VERSION ""

NS_ :

BS_: 500000

BU_: TITA_SENDER VCU BCM ADAS ICC GW

VAL_ 0x399 TrafficLightState 0 "Unknown" 1 "Red" 2 "Yellow_Flashing" 3 "Yellow" 4 "Red_Flashing" 5 "Unknown_5" 6 "Unknown_6" 7 "Green" ;
VAL_ 0x399 LightValid 0 "Invalid" 1 "Valid" ;
VAL_ 0x449 IntersectionReachable 0 "Not_Reachable" 1 "Reachable" ;
VAL_ 0x399 SignalPhaseID 0 "Phase_A" 1 "Phase_B" 2 "Phase_C" 3 "Phase_D" 4 "Phase_E" 5 "Phase_F" 6 "Phase_G" 7 "Phase_H" 8 "Phase_I" 9 "Phase_J" 10 "Phase_K" 11 "Phase_L" 12 "Phase_M" 13 "Phase_N" 14 "Phase_O" 15 "Phase_P" ;

CM_ VCU "Vehicle Control Unit - 整车控制器";
CM_ BCM "Body Control Module - 车身控制器";
CM_ ADAS "Advanced Driver Assistance System - 高级驾驶辅助系统";
CM_ ICC "Intelligent Cockpit Controller - 智能座舱/V2X";
CM_ TITA_SENDER "TITA CAN-BLE Transmitter - 无线发射器";
CM_ GW "Gateway - 网关";

BO_ 273 VehicleControlStatus: 8 ADAS
 SG_ VC_Active : 0|16@1+ (1,0) [0|65535] "" TITA_SENDER
 SG_ VC_Status : 16|16@1+ (1,0) [0|65535] "" TITA_SENDER

BO_ 325 GearDriveMode: 8 VCU
 SG_ Gear_Position : 29|2@1+ (1,0) [0|3] "" TITA_SENDER
 SG_ Drive_Mode : 12|4@1+ (1,0) [0|15] "" TITA_SENDER

BO_ 605 SteerAngle: 6 VCU
 SG_ SteerAngle_Status : 24|3@1+ (1,0) [0|7] "" TITA_SENDER
 SG_ SteerAngle_Value : 16|8@1+ (0.5,-64) [-64|63.5] "deg" TITA_SENDER

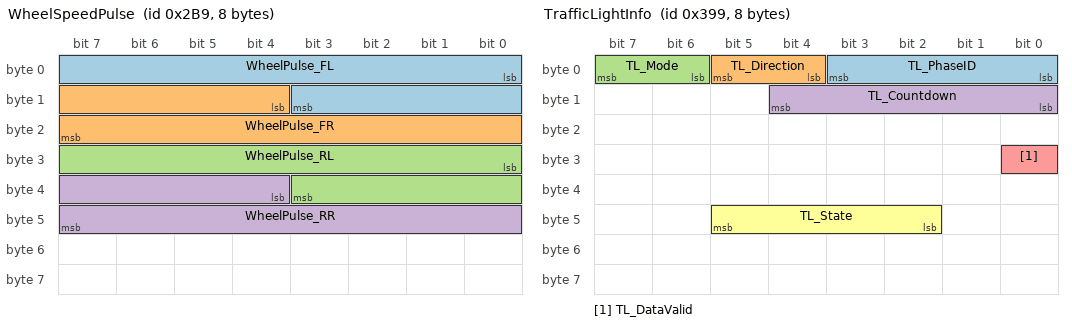
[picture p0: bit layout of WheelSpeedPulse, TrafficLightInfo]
BO_ 697 WheelSpeedPulse: 8 VCU
 SG_ WheelPulse_FL : 0|12@1+ (1,0) [0|4095] "" TITA_SENDER
 SG_ WheelPulse_FR : 12|12@1+ (1,0) [0|4095] "" TITA_SENDER
 SG_ WheelPulse_RL : 24|12@1+ (1,0) [0|4095] "" TITA_SENDER
 SG_ WheelPulse_RR : 36|12@1+ (1,0) [0|4095] "" TITA_SENDER

BO_ 905 VehicleSpeed: 8 VCU
 SG_ Vehicle_Speed : 0|10@1+ (0.1,0) [0|102.3] "km/h" TITA_SENDER

BO_ 921 TrafficLightInfo: 8 ICC
 SG_ TL_PhaseID : 0|4@1+ (1,0) [0|15] "" TITA_SENDER
 SG_ TL_Direction : 4|2@1+ (1,0) [0|3] "" TITA_SENDER
 SG_ TL_Mode : 6|2@1+ (1,0) [0|3] "" TITA_SENDER
 SG_ TL_Countdown : 8|5@1+ (1,0) [0|31] "s" TITA_SENDER
 SG_ TL_DataValid : 24|1@1+ (1,0) [0|1] "" TITA_SENDER
 SG_ TL_State : 42|4@1+ (1,0) [0|15] "" TITA_SENDER

BO_ 925 StopLineDistance: 5 ICC
 SG_ SLD_Status : 16|2@1+ (1,0) [0|3] "" TITA_SENDER
 SG_ SLD_Distance : 21|12@1+ (0.1,0) [0|409.5] "m" TITA_SENDER

BO_ 1097 IntersectionInfo: 3 ICC
 SG_ Intersection_Reachable : 3|1@1+ (1,0) [0|1] "" TITA_SENDER

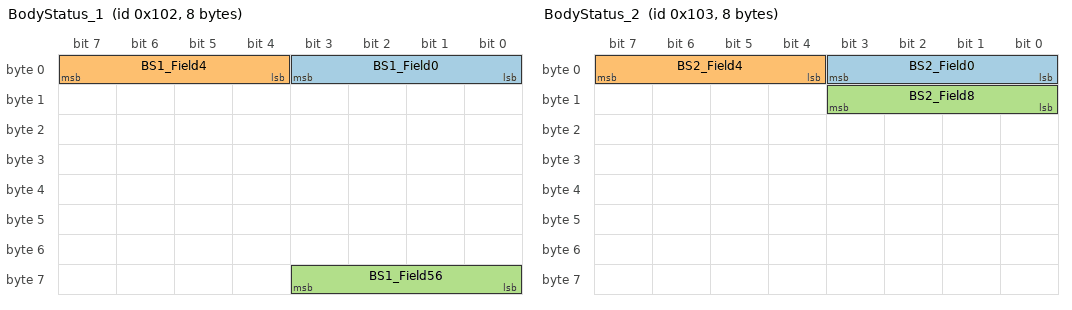
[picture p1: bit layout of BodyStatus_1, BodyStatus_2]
BO_ 258 BodyStatus_1: 8 BCM
 SG_ BS1_Field0 : 0|4@1+ (1,0) [0|15] "" TITA_SENDER
 SG_ BS1_Field4 : 4|4@1+ (1,0) [0|15] "" TITA_SENDER
 SG_ BS1_Field56 : 56|4@1+ (1,0) [0|15] "" TITA_SENDER

BO_ 259 BodyStatus_2: 8 BCM
 SG_ BS2_Field0 : 0|4@1+ (1,0) [0|15] "" TITA_SENDER
 SG_ BS2_Field4 : 4|4@1+ (1,0) [0|15] "" TITA_SENDER
 SG_ BS2_Field8 : 8|4@1+ (1,0) [0|15] "" TITA_SENDER

BO_ 280 BodyControl_1: 8 BCM
 SG_ BC1_Data : 0|64@1+ (1,0) [0|1.8446744e+19] "" TITA_SENDER

BO_ 297 BodyControl_2: 8 BCM
 SG_ BC2_Data : 0|64@1+ (1,0) [0|1.8446744e+19] "" TITA_SENDER

BO_ 306 BatteryInfo_1: 4 VCU
 SG_ Batt_Voltage : 8|16@1+ (0.1,0) [0|6553.5] "V" TITA_SENDER
 SG_ Batt_Current : 24|16@1- (0.1,0) [-3276.8|3276.7] "A" TITA_SENDER

BO_ 469 PowerTrain_1: 8 VCU
 SG_ PT1_Data : 0|64@1+ (1,0) [0|1.8446744e+19] "" TITA_SENDER

BO_ 472 PowerTrain_2: 8 VCU
 SG_ PT2_Data : 0|64@1+ (1,0) [0|1.8446744e+19] "" TITA_SENDER

BO_ 530 ChassisInfo_1: 8 VCU
 SG_ CI1_Field0 : 0|3@1+ (1,0) [0|7] "" TITA_SENDER
 SG_ CI1_Field11 : 11|3@1+ (1,0) [0|7] "" TITA_SENDER

BO_ 537 ChassisInfo_2: 8 VCU
 SG_ CI2_Data : 0|64@1+ (1,0) [0|1.8446744e+19] "" TITA_SENDER

BO_ 552 SafetySystem_1: 8 ADAS
 SG_ SS1_Data : 0|64@1+ (1,0) [0|1.8446744e+19] "" TITA_SENDER

BO_ 579 SensorCluster_1: 8 ADAS
 SG_ SC1_Field0 : 0|3@1+ (1,0) [0|7] "" TITA_SENDER
 SG_ SC1_Field30 : 30|11@1+ (1,0) [0|2047] "" TITA_SENDER

BO_ 599 BodyStatus_3: 8 BCM
 SG_ BS3_Data : 0|64@1+ (1,0) [0|1.8446744e+19] "" TITA_SENDER

BO_ 602 BodyStatus_4: 8 BCM
 SG_ BS4_Data : 0|64@1+ (1,0) [0|1.8446744e+19] "" TITA_SENDER

BO_ 614 DriverInput_1: 8 VCU
 SG_ DI1_Field0 : 0|11@1+ (1,0) [0|2047] "" TITA_SENDER

BO_ 627 DriverInput_2: 8 VCU
 SG_ DI2_Data : 0|64@1+ (1,0) [0|1.8446744e+19] "" TITA_SENDER

BO_ 659 ThermalMgmt_1: 8 VCU
 SG_ TM1_Data : 0|64@1+ (1,0) [0|1.8446744e+19] "" TITA_SENDER

BO_ 694 LightingStatus: 2 BCM
 SG_ Light_State : 10|1@1+ (1,0) [0|1] "" TITA_SENDER

BO_ 723 ThermalMgmt_2: 8 VCU
 SG_ TM2_Data : 0|64@1+ (1,0) [0|1.8446744e+19] "" TITA_SENDER

BO_ 737 HVAC_Control_1: 8 BCM
 SG_ HVAC1_Data : 0|64@1+ (1,0) [0|1.8446744e+19] "" TITA_SENDER

BO_ 741 HVAC_Control_2: 8 BCM
 SG_ HVAC2_Field0 : 0|11@1+ (1,0) [0|2047] "" TITA_SENDER

BO_ 755 Infotainment_1: 8 ICC
 SG_ INFO1_Data : 0|64@1+ (1,0) [0|1.8446744e+19] "" TITA_SENDER

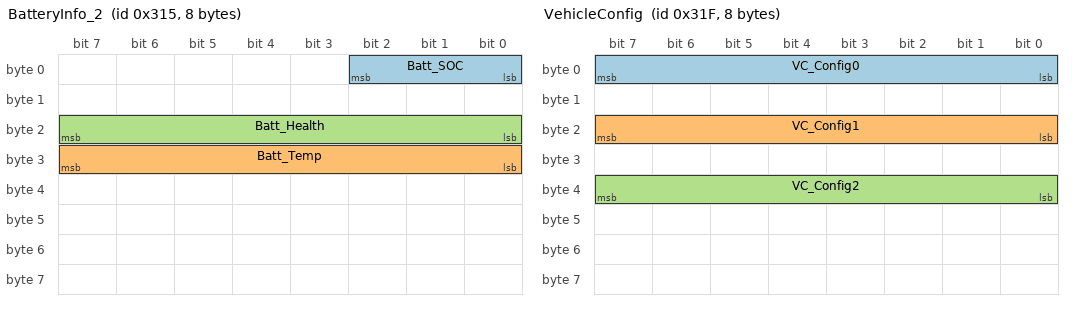
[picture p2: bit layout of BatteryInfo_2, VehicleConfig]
BO_ 789 BatteryInfo_2: 8 VCU
 SG_ Batt_SOC : 0|3@1+ (1,0) [0|7] "" TITA_SENDER
 SG_ Batt_Temp : 24|8@1+ (1,-40) [-40|215] "degC" TITA_SENDER
 SG_ Batt_Health : 16|8@1+ (1,0) [0|255] "" TITA_SENDER

BO_ 799 VehicleConfig: 8 GW
 SG_ VC_Config0 : 0|8@1+ (1,0) [0|255] "" TITA_SENDER
 SG_ VC_Config1 : 16|8@1+ (1,0) [0|255] "" TITA_SENDER
 SG_ VC_Config2 : 32|8@1+ (1,0) [0|255] "" TITA_SENDER

BO_ 801 Diagnostic_1: 8 GW
 SG_ DIAG1_Data : 0|64@1+ (1,0) [0|1.8446744e+19] "" TITA_SENDER

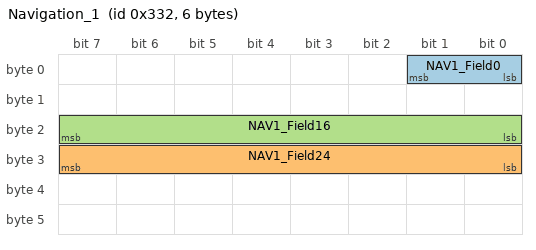
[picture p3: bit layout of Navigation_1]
BO_ 818 Navigation_1: 6 ICC
 SG_ NAV1_Field0 : 0|2@1+ (1,0) [0|3] "" TITA_SENDER
 SG_ NAV1_Field24 : 24|8@1+ (1,0) [0|255] "" TITA_SENDER
 SG_ NAV1_Field16 : 16|8@1+ (1,0) [0|255] "" TITA_SENDER

BO_ 820 Navigation_2: 8 ICC
 SG_ NAV2_Data : 0|64@1+ (1,0) [0|1.8446744e+19] "" TITA_SENDER

BO_ 825 ADAS_Sensor_1: 8 ADAS
 SG_ ADAS1_Data : 0|64@1+ (1,0) [0|1.8446744e+19] "" TITA_SENDER

BO_ 826 ADAS_Sensor_2: 8 ADAS
 SG_ ADAS2_Field0 : 0|7@1+ (1,0) [0|127] "" TITA_SENDER
 SG_ ADAS2_Field10 : 10|10@1+ (0.1,0) [0|102.3] "" TITA_SENDER

BO_ 851 ChargerInfo_1: 8 VCU
 SG_ CHG1_Data : 0|64@1+ (1,0) [0|1.8446744e+19] "" TITA_SENDER

BO_ 878 ChargerInfo_2: 8 VCU
 SG_ CHG2_Data : 0|64@1+ (1,0) [0|1.8446744e+19] "" TITA_SENDER

BO_ 886 BatteryPack_1: 8 VCU
 SG_ BP1_Field0 : 0|3@1+ (1,0) [0|7] "" TITA_SENDER
 SG_ BP1_FieldN : 24|8@1+ (1,0) [0|255] "" TITA_SENDER

BO_ 929 MotorControl_1: 8 VCU
 SG_ MC1_Data : 0|64@1+ (1,0) [0|1.8446744e+19] "" TITA_SENDER

BO_ 947 MotorControl_2: 4 VCU
 SG_ MC2_Field9 : 9|3@1+ (1,0) [0|7] "" TITA_SENDER

BO_ 950 MotorControl_3: 8 VCU
 SG_ MC3_Data : 0|64@1+ (1,0) [0|1.8446744e+19] "" TITA_SENDER

BO_ 962 SystemStatus_1: 8 GW
 SG_ SS_Data : 0|64@1+ (1,0) [0|1.8446744e+19] "" TITA_SENDER

BO_ 978 OdometerPosition: 8 ICC
 SG_ Latitude : 0|32@1+ (1e-7,0) [-90|90] "deg" TITA_SENDER
 SG_ Longitude : 32|32@1+ (1e-7,0) [-180|180] "deg" TITA_SENDER

BO_ 991 SystemStatus_2: 8 GW
 SG_ SS2_Data : 0|64@1+ (1,0) [0|1.8446744e+19] "" TITA_SENDER

BO_ 995 SystemStatus_3: 8 GW
 SG_ SS3_Data : 0|64@1+ (1,0) [0|1.8446744e+19] "" TITA_SENDER

BO_ 1013 SystemStatus_4: 8 GW
 SG_ SS4_Data : 0|64@1+ (1,0) [0|1.8446744e+19] "" TITA_SENDER

BO_ 1014 SystemStatus_5: 8 GW
 SG_ SS5_Data : 0|64@1+ (1,0) [0|1.8446744e+19] "" TITA_SENDER

BO_ 1022 NetworkMgmt: 8 GW
 SG_ NM_Data : 0|64@1+ (1,0) [0|1.8446744e+19] "" TITA_SENDER

BO_ 1657 ExtendedDiag: 8 GW
 SG_ EXTD_Data : 0|64@1+ (1,0) [0|1.8446744e+19] "" TITA_SENDER

CM_ BO_ 273 "Vehicle control status - 车辆控制状态 (来源: taskChassisBus)";
CM_ BO_ 325 "Gear position and drive mode - 档位与驾驶模式";
CM_ BO_ 605 "Steering wheel angle - 方向盘转角";
CM_ BO_ 697 "Wheel speed pulses - 轮速脉冲";
CM_ BO_ 905 "Vehicle speed - 车速信号";
CM_ BO_ 921 "Traffic light V2X information - 红绿灯V2X信息";
CM_ BO_ 925 "Stop line distance - 停止线距离";
CM_ BO_ 1097 "Intersection reachability - 路口可达性";
CM_ BO_ 978 "GPS position from odometer - GPS经纬度";
CM_ BO_ 306 "Battery voltage and current - 电池电压电流";
CM_ BO_ 789 "Battery SOC and temperature - 电池SOC和温度";
CM_ BO_ 799 "Vehicle configuration parameters - 车辆配置参数";
CM_ BO_ 826 "ADAS sensor data - ADAS传感器数据";

CM_ SG_ 273 VC_Active "Vehicle control system activation status";
CM_ SG_ 325 Gear_Position "0=P 1=R 2=N 3=D";
CM_ SG_ 325 Drive_Mode "0=Normal 1=ECO 2=Sport 3=Comfort";
CM_ SG_ 605 SteerAngle_Value "Steering angle in degrees, positive=left";
CM_ SG_ 697 WheelPulse_FL "Front-left wheel speed pulse count";
CM_ SG_ 905 Vehicle_Speed "Vehicle speed in km/h";
CM_ SG_ 921 TL_State "0=Unknown 1=Red 2=Yellow_Flashing 3=Yellow 4=Red_Flashing 7=Green";
CM_ SG_ 921 TL_Countdown "Traffic light remaining time in seconds";
CM_ SG_ 921 TL_PhaseID "Intersection signal phase identifier";
CM_ SG_ 925 SLD_Distance "Distance to stop line in meters (0.1m resolution)";
CM_ SG_ 1097 Intersection_Reachable "Whether the intersection can be reached";
CM_ SG_ 978 Latitude "Latitude in degrees, 1e-7 resolution";
CM_ SG_ 978 Longitude "Longitude in degrees, 1e-7 resolution";
CM_ SG_ 306 Batt_Voltage "Battery total voltage";
CM_ SG_ 306 Batt_Current "Battery current, positive=discharge";
CM_ SG_ 789 Batt_SOC "Battery state of charge encoded value";
CM_ SG_ 789 Batt_Temp "Battery temperature in Celsius";

BA_DEF_ "BusType" STRING ;
BA_DEF_ BO_ "GenMsgCycleTime" INT 0 60000 ;
BA_DEF_DEF_ "BusType" "CAN";
BA_DEF_DEF_ "GenMsgCycleTime" 0;

# 周期时间设置 (ms)
BA_ "GenMsgCycleTime" BO_ 273 20;
BA_ "GenMsgCycleTime" BO_ 325 100;
BA_ "GenMsgCycleTime" BO_ 605 10;
BA_ "GenMsgCycleTime" BO_ 697 10;
BA_ "GenMsgCycleTime" BO_ 905 10;
BA_ "GenMsgCycleTime" BO_ 921 100;
BA_ "GenMsgCycleTime" BO_ 925 100;
BA_ "GenMsgCycleTime" BO_ 1097 200;
BA_ "GenMsgCycleTime" BO_ 258 100;
BA_ "GenMsgCycleTime" BO_ 259 100;
BA_ "GenMsgCycleTime" BO_ 306 100;
BA_ "GenMsgCycleTime" BO_ 599 50;
BA_ "GenMsgCycleTime" BO_ 694 500;
BA_ "GenMsgCycleTime" BO_ 789 100;
BA_ "GenMsgCycleTime" BO_ 799 1000;
BA_ "GenMsgCycleTime" BO_ 978 100;
